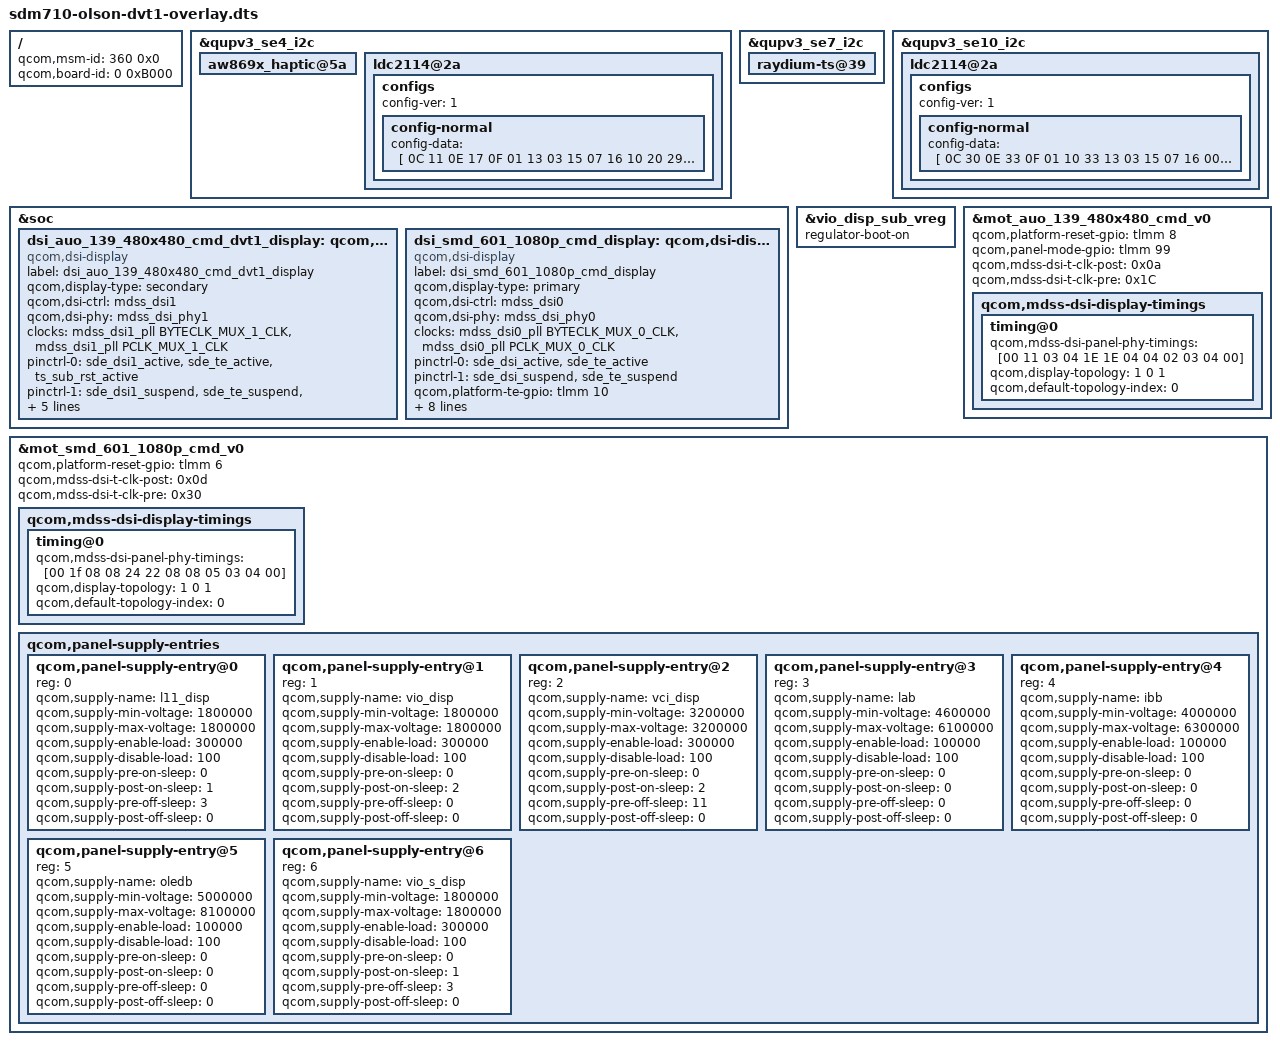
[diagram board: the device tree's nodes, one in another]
/* Copyright (c) 2018, The Linux Foundation. All rights reserved.
 *
 * This program is free software; you can redistribute it and/or modify
 * it under the terms of the GNU General Public License version 2 and
 * only version 2 as published by the Free Software Foundation.
 *
 * This program is distributed in the hope that it will be useful,
 * but WITHOUT ANY WARRANTY; without even the implied warranty of
 * MERCHANTABILITY or FITNESS FOR A PARTICULAR PURPOSE.  See the
 * GNU General Public License for more details.
 */

/dts-v1/;
/plugin/;

#include "sdm710-olson-common-overlay.dtsi"
#include "dsi-panel-mot-smd-601-1080p-olson-cmd.dtsi"
#include "dsi-panel-mot-auo-139-480x480-olson-cmd.dtsi"

/ {
	qcom,msm-id = <360 0x0>;
	qcom,board-id = <0 0xB000>;
};

/*
 * Olson HW rev DVT1 specific changes go here
 */
&qupv3_se4_i2c {
	aw869x_haptic@5a {
		status = "ok";
	};

	ldc2114@2a {
		status = "ok";
		configs {
			config-ver = <1>;
			config-normal {
				config-data = [
					0C 11 /*EN*/
					0E 17 /*GAIN0*/
					0F 01 /*LP_SCAN_RATE*/
					13 03 /*LP_BASE_INC*/
					15 07 /*NP_BASE_INC*/
					16 10 /*BTPAUSE_MAXWIN*/
					20 29 /*SENSOR0_CFG*/
					28 00 /*FTF1_2*/
				];
			};
		};
	};
};

&qupv3_se7_i2c {
	raydium-ts@39 {
		status = "ok";
	};
};

&qupv3_se10_i2c {
	ldc2114@2a {
		status = "ok";
		configs {
			config-ver = <1>;
			config-normal {
				config-data = [
					0C 30 /*EN*/
					0E 33 /*GAIN0*/
					0F 01 /*LP_SCAN_RATE*/
					10 33 /*GAIN1*/
					13 03 /*LP_BASE_INC*/
					15 07 /*NP_BASE_INC*/
					16 00 /*BTPAUSE_MAXWIN*/
					1C 00 /*OPOL_DPOL*/
					20 59 /*SENSOR0_CFG*/
					22 59 /*SENSOR1_CFG*/
				];
			};
		};
	};
};

&soc {
	dsi_auo_139_480x480_cmd_dvt1_display: qcom,dsi-display@22 {
		compatible = "qcom,dsi-display";
		label = "dsi_auo_139_480x480_cmd_dvt1_display";
		qcom,display-type = "secondary";

		qcom,dsi-ctrl = <&mdss_dsi1>;
		qcom,dsi-phy = <&mdss_dsi_phy1>;
		clocks = <&mdss_dsi1_pll BYTECLK_MUX_1_CLK>,
			<&mdss_dsi1_pll PCLK_MUX_1_CLK>;
		clock-names = "src_byte_clk", "src_pixel_clk";

		pinctrl-names = "panel_active", "panel_suspend";
		pinctrl-0 = <&sde_dsi1_active &sde_te_active
						&ts_sub_rst_active>;
		pinctrl-1 = <&sde_dsi1_suspend &sde_te_suspend
						&ts_sub_rst_suspend>;
		qcom,platform-te-gpio = <&tlmm 11 0>;
		qcom,dsi-panel = <&mot_auo_139_480x480_cmd_v0>;
		vci_disp-supply = <&vci_disp_sub_vreg>;
		vio_disp-supply = <&vio_disp_sub_vreg>;
	};

	dsi_smd_601_1080p_cmd_display: qcom,dsi-display@18 {
		compatible = "qcom,dsi-display";
		label = "dsi_smd_601_1080p_cmd_display";
		qcom,display-type = "primary";

		qcom,dsi-ctrl = <&mdss_dsi0>;
		qcom,dsi-phy = <&mdss_dsi_phy0>;
		clocks = <&mdss_dsi0_pll BYTECLK_MUX_0_CLK>,
			<&mdss_dsi0_pll PCLK_MUX_0_CLK>;
		clock-names = "src_byte_clk", "src_pixel_clk";

		pinctrl-names = "panel_active", "panel_suspend";
		pinctrl-0 = <&sde_dsi_active &sde_te_active>;
		pinctrl-1 = <&sde_dsi_suspend &sde_te_suspend>;
		qcom,platform-te-gpio = <&tlmm 10 0>;
		qcom,dsi-panel = <&mot_smd_601_1080p_cmd_v0>;
		l11_disp-supply = <&pm660_l11>;
		vci_disp-supply = <&vci_disp_vreg>;
		vio_disp-supply = <&vio_disp_vreg>;
		lab-supply = <&lab_regulator>;
		ibb-supply = <&ibb_regulator>;
		oledb-supply = <&pm660a_oledb>;
		vio_s_disp-supply = <&vio_disp_sub_vreg>;
	};
};

&vio_disp_sub_vreg {
	regulator-boot-on;
};

/*
 * The CLI display of the DVT1 is a in-cell display which has one controller
 * to control both the display and touch, therefore the touch reset will
 * be part of the display init and deinit seq. This in-cell display is only
 * used in the DVT1, therefore for temporarty solution is using current display
 * feature which is using qcom,panel-mode-gpio as the touch reset GPIO
 */
&mot_auo_139_480x480_cmd_v0 {
	qcom,platform-reset-gpio = <&tlmm 8 0>;
	qcom,panel-mode-gpio = <&tlmm 99 0>;
	qcom,mdss-dsi-t-clk-post = <0x0a>;
	qcom,mdss-dsi-t-clk-pre = <0x1C>;

	qcom,mdss-dsi-display-timings {
		timing@0{
			qcom,mdss-dsi-panel-phy-timings = [00 11 03 04 1E 1E 04
							 04 02 03 04 00];
			qcom,display-topology = <1 0 1>;
			qcom,default-topology-index = <0>;
		};
	};
};

&mot_smd_601_1080p_cmd_v0 {
	qcom,platform-reset-gpio = <&tlmm 6 0>;
	qcom,mdss-dsi-t-clk-post = <0x0d>;
	qcom,mdss-dsi-t-clk-pre = <0x30>;
	qcom,mdss-dsi-display-timings {
		timing@0{
			qcom,mdss-dsi-panel-phy-timings = [00 1f 08 08 24 22 08
							08 05 03 04 00];
			qcom,display-topology = <1 0 1>;
			qcom,default-topology-index = <0>;
		};
	};

	qcom,panel-supply-entries {
		#address-cells = <1>;
		#size-cells = <0>;

		qcom,panel-supply-entry@0 {
			reg = <0>;
			qcom,supply-name = "l11_disp";
			qcom,supply-min-voltage = <1800000>;
			qcom,supply-max-voltage = <1800000>;
			qcom,supply-enable-load = <300000>;
			qcom,supply-disable-load = <100>;
			qcom,supply-pre-on-sleep = <0>;
			qcom,supply-post-on-sleep = <1>;
			qcom,supply-pre-off-sleep = <3>;
			qcom,supply-post-off-sleep = <0>;
		};

		qcom,panel-supply-entry@1 {
			reg = <1>;
			qcom,supply-name = "vio_disp";
			qcom,supply-min-voltage = <1800000>;
			qcom,supply-max-voltage = <1800000>;
			qcom,supply-enable-load = <300000>;
			qcom,supply-disable-load = <100>;
			qcom,supply-pre-on-sleep = <0>;
			qcom,supply-post-on-sleep = <2>;
			qcom,supply-pre-off-sleep = <0>;
			qcom,supply-post-off-sleep = <0>;
		};

		qcom,panel-supply-entry@2 {
			reg = <2>;
			qcom,supply-name = "vci_disp";
			qcom,supply-min-voltage = <3200000>;
			qcom,supply-max-voltage = <3200000>;
			qcom,supply-enable-load = <300000>;
			qcom,supply-disable-load = <100>;
			qcom,supply-pre-on-sleep = <0>;
			qcom,supply-post-on-sleep = <2>;
			qcom,supply-pre-off-sleep = <11>;
			qcom,supply-post-off-sleep = <0>;
		};

		qcom,panel-supply-entry@3 {
			reg = <3>;
			qcom,supply-name = "lab";
			qcom,supply-min-voltage = <4600000>;
			qcom,supply-max-voltage = <6100000>;
			qcom,supply-enable-load = <100000>;
			qcom,supply-disable-load = <100>;
			qcom,supply-pre-on-sleep = <0>;
			qcom,supply-post-on-sleep = <0>;
			qcom,supply-pre-off-sleep = <0>;
			qcom,supply-post-off-sleep = <0>;
		};

		qcom,panel-supply-entry@4 {
			reg = <4>;
			qcom,supply-name = "ibb";
			qcom,supply-min-voltage = <4000000>;
			qcom,supply-max-voltage = <6300000>;
			qcom,supply-enable-load = <100000>;
			qcom,supply-disable-load = <100>;
			qcom,supply-pre-on-sleep = <0>;
			qcom,supply-post-on-sleep = <0>;
			qcom,supply-pre-off-sleep = <0>;
			qcom,supply-post-off-sleep = <0>;
		};

		qcom,panel-supply-entry@5 {
			reg = <5>;
			qcom,supply-name = "oledb";
			qcom,supply-min-voltage = <5000000>;
			qcom,supply-max-voltage = <8100000>;
			qcom,supply-enable-load = <100000>;
			qcom,supply-disable-load = <100>;
			qcom,supply-pre-on-sleep = <0>;
			qcom,supply-post-on-sleep = <0>;
			qcom,supply-pre-off-sleep = <0>;
			qcom,supply-post-off-sleep = <0>;
		};

		qcom,panel-supply-entry@6 {
			reg = <6>;
			qcom,supply-name = "vio_s_disp";
			qcom,supply-min-voltage = <1800000>;
			qcom,supply-max-voltage = <1800000>;
			qcom,supply-enable-load = <300000>;
			qcom,supply-disable-load = <100>;
			qcom,supply-pre-on-sleep = <0>;
			qcom,supply-post-on-sleep = <1>;
			qcom,supply-pre-off-sleep = <3>;
			qcom,supply-post-off-sleep = <0>;
		};
	};
};
